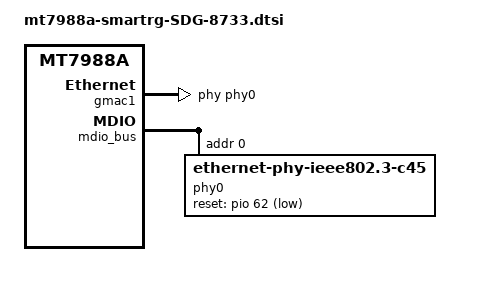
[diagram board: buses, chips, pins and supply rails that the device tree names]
// SPDX-License-Identifier: (GPL-2.0 OR MIT)
/*
 * Copyright (C) 2023 SmartRG Inc.
 * Author: Chad Monroe <chad.monroe@smartrg.com>
 *
 * SDG-8733: Mt. Stuart phase 1 with AQR113C 10G WAN.
 */

#include "mt7988a-smartrg-mt-stuart-phase1.dtsi"

&gmac1 {
	phy = <&phy0>;
};

&mdio_bus {
	phy0: ethernet-phy@0 {
		/* AQR113C */
		compatible = "ethernet-phy-ieee802.3-c45";
		reg = <0>;

		reset-gpios = <&pio 62 GPIO_ACTIVE_LOW>;
		reset-assert-us = <100000>;
		reset-deassert-us = <1000000>;

		leds {
			#address-cells = <1>;
			#size-cells = <0>;

			led@0 {
				reg = <0>;
				function = LED_FUNCTION_WAN;
				color = <LED_COLOR_ID_GREEN>;
			};

			led@1 {
				reg = <1>;
				function = LED_FUNCTION_WAN;
				color = <LED_COLOR_ID_ORANGE>;
			};

			led@2 {
				reg = <2>;
				function = LED_FUNCTION_WAN;
				color = <LED_COLOR_ID_WHITE>;
				active-high;
			};
		};
	};
};
